# ESP32-S31 register map
Vendor: ESPRESSIF SYSTEMS (SHANGHAI) CO., LTD.; Series: ESP32 S-Series; File version: 1
CPU: RV32IMAFC r0p0, little endian, no MPU, FPU, 0 interrupt priority bits
Address unit: 32 bits
Registers are 32-bit, read-write, reset 0x0 unless marked. A register's access mark holds for its fields unless they carry their own. Offsets are from the block's base; [hi:lo] are bit positions; {n}, {i} and the like mark numbered series.

## GPIO_EXT — GPIO_EXT Peripheral
Base 0x20583E00
0x00 CLOCK_GATE — Clock Gating Configure Register
  [0] CLK_EN — Clock enable bit of configuration registers for sigma delta modulation.
0x04 SIGMADELTA_MISC — MISC Register
  [0] SIGMADELTA_CLK_EN — Configures whether or not to enable the clock for sigma delta modulation.\\ 0: Not enable\\ 1: Enable\\%\label{fielddesc:GPIOSDSPISWAP}- [GPIOSD_SPI_SWAP] Reserved.
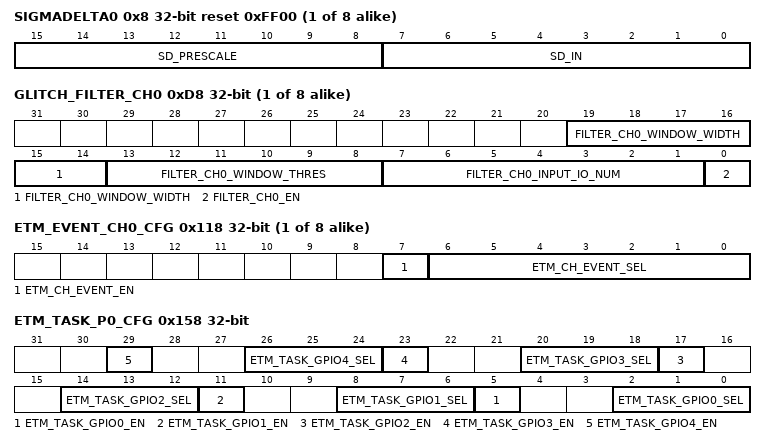
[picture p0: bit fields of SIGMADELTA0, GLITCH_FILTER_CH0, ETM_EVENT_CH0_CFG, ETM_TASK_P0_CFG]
{0x8+4i} SIGMADELTA{i} (i=0..7) reset 0xFF00 — Duty cycle configuration register for SDM channel {i}
  [15:8] SD_PRESCALE — Configures the divider value to divide IO MUX operating clock. \\
  [7:0] SD_IN — Configures the duty cycle of sigma delta modulation output. \\
{0xD8+4i} GLITCH_FILTER_CH{i} (i=0..7) — Glitch Filter Configure Register of Channel{i}
  [19:14] FILTER_CH0_WINDOW_WIDTH — Configures the window width for Glitch Filter. The effective value of window width is 0 ~ 63. \\ Measurement unit: IO MUX operating clock cycle\\
  [13:8] FILTER_CH0_WINDOW_THRES — Configures the window threshold for Glitch Filter. The window threshold should be less than or equal to GPIOSD_FILTER_CH%s_WINDOW_WIDTH.\\ %see DOC-4768\\ Measurement unit: IO MUX operating clock cycle\\
  [7:1] FILTER_CH0_INPUT_IO_NUM — Configures to select the input GPIO for Glitch Filter. \\ 0: Select GPIO0\\ 1: Select GPIO1\\ ......\\ 61: Select GPIO61\\ 62: Select GPIO62\\ 63 ~ 127: Reserved\\
  [0] FILTER_CH0_EN — Configures whether or not to enable channel %s of Glitch Filter.\\ 0: Not enable\\ 1: Enable\\
{0x118+4i} ETM_EVENT_CH{i}_CFG (i=0..7) — ETM configuration register for channel {i}
  [7] ETM_CH_EVENT_EN — Configures whether or not to enable ETM event send.\\ 0: Not enable\\ 1: Enable\\
  [6:0] ETM_CH_EVENT_SEL — Configures to select GPIO for ETM event channel.\\ 0: Select GPIO0\\ 1: Select GPIO1\\ ......\\ 61: Select GPIO61\\ 62: Select GPIO62\\ 63 ~ 127: Reserved\\
0x158 ETM_TASK_P0_CFG — GPIO selection register 0 for ETM
  [6n+5] ETM_TASK_GPIO{n}_EN (n=0..4) — Configures whether or not to enable GPIO{n} to response ETM task.\\ 0: Not enable\\ 1: Enable\\
  [6n+2:6n] ETM_TASK_GPIO{n}_SEL (n=0..4) — Configures to select an ETM task channel for GPIO{n}.\\ 0: Select channel 0\\ 1: Select channel 1\\ ......\\ 7: Select channel 7\\
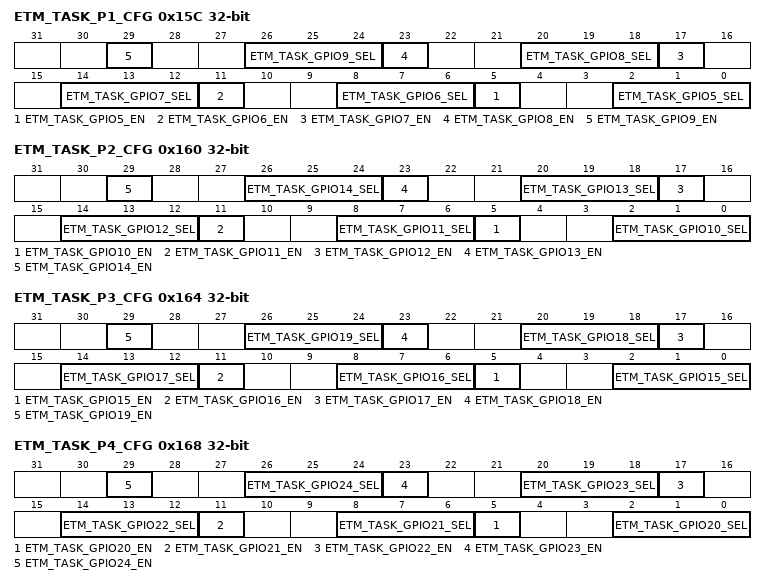
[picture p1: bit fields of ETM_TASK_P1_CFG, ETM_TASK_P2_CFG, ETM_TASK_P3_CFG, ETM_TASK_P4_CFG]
0x15C ETM_TASK_P1_CFG — GPIO selection register 1 for ETM
  [6n-25] ETM_TASK_GPIO{n}_EN (n=5..9) — Configures whether or not to enable GPIO{n} to response ETM task.\\ 0: Not enable\\ 1: Enable\\
  [6n-28:6n-30] ETM_TASK_GPIO{n}_SEL (n=5..9) — Configures to select an ETM task channel for GPIO{n}.\\ 0: Select channel 0\\ 1: Select channel 1\\ ......\\ 7: Select channel 7\\
0x160 ETM_TASK_P2_CFG — GPIO selection register 2 for ETM
  [6n-55] ETM_TASK_GPIO{n}_EN (n=10..14) — Configures whether or not to enable GPIO{n} to response ETM task.\\ 0: Not enable\\ 1: Enable\\
  [6n-58:6n-60] ETM_TASK_GPIO{n}_SEL (n=10..14) — Configures to select an ETM task channel for GPIO{n}.\\ 0: Select channel 0\\ 1: Select channel 1\\ ......\\ 7: Select channel 7\\
0x164 ETM_TASK_P3_CFG — GPIO selection register 3 for ETM
  [6n-85] ETM_TASK_GPIO{n}_EN (n=15..19) — Configures whether or not to enable GPIO{n} to response ETM task.\\ 0: Not enable\\ 1: Enable\\
  [6n-88:6n-90] ETM_TASK_GPIO{n}_SEL (n=15..19) — Configures to select an ETM task channel for GPIO{n}.\\ 0: Select channel 0\\ 1: Select channel 1\\ ......\\ 7: Select channel 7\\
0x168 ETM_TASK_P4_CFG — GPIO selection register 4 for ETM
  [6n-115] ETM_TASK_GPIO{n}_EN (n=20..24) — Configures whether or not to enable GPIO{n} to response ETM task.\\ 0: Not enable\\ 1: Enable\\
  [6n-118:6n-120] ETM_TASK_GPIO{n}_SEL (n=20..24) — Configures to select an ETM task channel for GPIO{n}.\\ 0: Select channel 0\\ 1: Select channel 1\\ ......\\ 7: Select channel 7\\
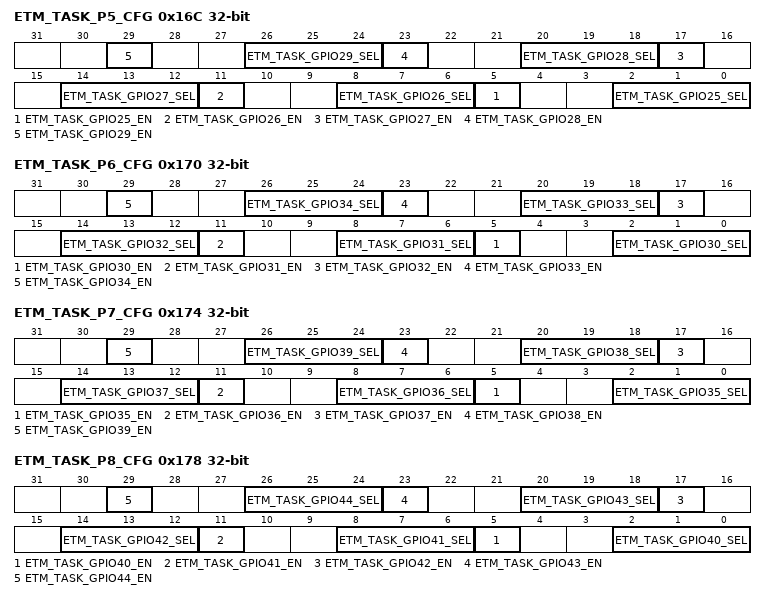
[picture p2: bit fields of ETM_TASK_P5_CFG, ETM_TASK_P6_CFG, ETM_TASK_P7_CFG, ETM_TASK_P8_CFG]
0x16C ETM_TASK_P5_CFG — GPIO selection register 5 for ETM
  [6n-145] ETM_TASK_GPIO{n}_EN (n=25..29) — Configures whether or not to enable GPIO{n} to response ETM task.\\ 0: Not enable\\ 1: Enable\\
  [6n-148:6n-150] ETM_TASK_GPIO{n}_SEL (n=25..29) — Configures to select an ETM task channel for GPIO{n}.\\ 0: Select channel 0\\ 1: Select channel 1\\ ......\\ 7: Select channel 7\\
0x170 ETM_TASK_P6_CFG — GPIO selection register 6 for ETM
  [6n-175] ETM_TASK_GPIO{n}_EN (n=30..34) — Configures whether or not to enable GPIO{n} to response ETM task.\\ 0: Not enable\\ 1: Enable\\
  [6n-178:6n-180] ETM_TASK_GPIO{n}_SEL (n=30..34) — Configures to select an ETM task channel for GPIO{n}.\\ 0: Select channel 0\\ 1: Select channel 1\\ ......\\ 7: Select channel 7\\
0x174 ETM_TASK_P7_CFG — GPIO selection register 7 for ETM
  [6n-205] ETM_TASK_GPIO{n}_EN (n=35..39) — Configures whether or not to enable GPIO{n} to response ETM task.\\ 0: Not enable\\ 1: Enable\\
  [6n-208:6n-210] ETM_TASK_GPIO{n}_SEL (n=35..39) — Configures to select an ETM task channel for GPIO{n}.\\ 0: Select channel 0\\ 1: Select channel 1\\ ......\\ 7: Select channel 7\\
0x178 ETM_TASK_P8_CFG — GPIO selection register 8 for ETM
  [6n-235] ETM_TASK_GPIO{n}_EN (n=40..44) — Configures whether or not to enable GPIO{n} to response ETM task.\\ 0: Not enable\\ 1: Enable\\
  [6n-238:6n-240] ETM_TASK_GPIO{n}_SEL (n=40..44) — Configures to select an ETM task channel for GPIO{n}.\\ 0: Select channel 0\\ 1: Select channel 1\\ ......\\ 7: Select channel 7\\
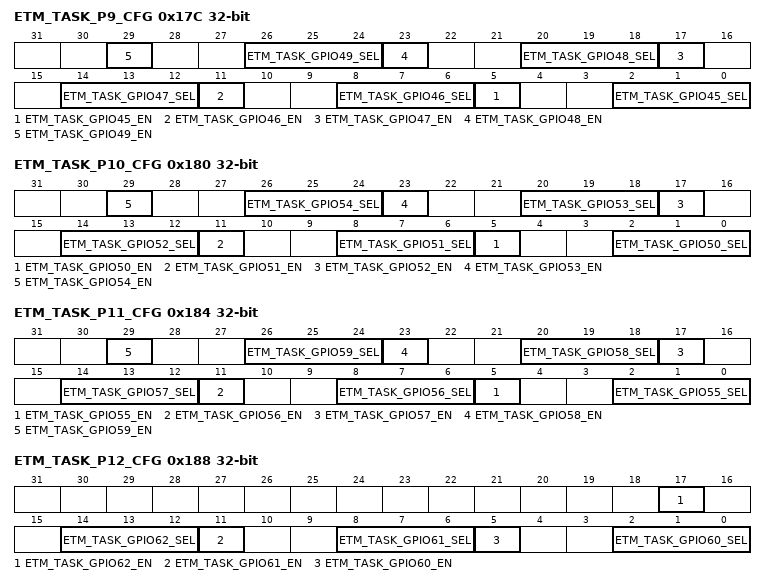
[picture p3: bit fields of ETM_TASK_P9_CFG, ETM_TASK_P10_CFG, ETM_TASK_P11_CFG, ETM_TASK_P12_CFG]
0x17C ETM_TASK_P9_CFG — GPIO selection register 9 for ETM
  [6n-265] ETM_TASK_GPIO{n}_EN (n=45..49) — Configures whether or not to enable GPIO{n} to response ETM task.\\ 0: Not enable\\ 1: Enable\\
  [6n-268:6n-270] ETM_TASK_GPIO{n}_SEL (n=45..49) — Configures to select an ETM task channel for GPIO{n}.\\ 0: Select channel 0\\ 1: Select channel 1\\ ......\\ 7: Select channel 7\\
0x180 ETM_TASK_P10_CFG — GPIO selection register 10 for ETM
  [6n-295] ETM_TASK_GPIO{n}_EN (n=50..54) — Configures whether or not to enable GPIO{n} to response ETM task.\\ 0: Not enable\\ 1: Enable\\
  [6n-298:6n-300] ETM_TASK_GPIO{n}_SEL (n=50..54) — Configures to select an ETM task channel for GPIO{n}.\\ 0: Select channel 0\\ 1: Select channel 1\\ ......\\ 7: Select channel 7\\
0x184 ETM_TASK_P11_CFG — GPIO selection register 11 for ETM
  [6n-325] ETM_TASK_GPIO{n}_EN (n=55..59) — Configures whether or not to enable GPIO{n} to response ETM task.\\ 0: Not enable\\ 1: Enable\\
  [6n-328:6n-330] ETM_TASK_GPIO{n}_SEL (n=55..59) — Configures to select an ETM task channel for GPIO{n}.\\ 0: Select channel 0\\ 1: Select channel 1\\ ......\\ 7: Select channel 7\\
0x188 ETM_TASK_P12_CFG — GPIO selection register 12 for ETM
  [17] ETM_TASK_GPIO62_EN — Configures whether or not to enable GPIO62 to response ETM task.\\ 0: Not enable\\ 1: Enable\\
  [14:12] ETM_TASK_GPIO62_SEL — Configures to select an ETM task channel for GPIO62.\\ 0: Select channel 0\\ 1: Select channel 1\\ ......\\ 7: Select channel 7\\
  [11] ETM_TASK_GPIO61_EN — Configures whether or not to enable GPIO61 to response ETM task.\\ 0: Not enable\\ 1: Enable\\
  [8:6] ETM_TASK_GPIO61_SEL — Configures to select an ETM task channel for GPIO61.\\ 0: Select channel 0\\ 1: Select channel 1\\ ......\\ 7: Select channel 7\\
  [5] ETM_TASK_GPIO60_EN — Configures whether or not to enable GPIO60 to response ETM task.\\ 0: Not enable\\ 1: Enable\\
  [2:0] ETM_TASK_GPIO60_SEL — Configures to select an ETM task channel for GPIO60.\\ 0: Select channel 0\\ 1: Select channel 1\\ ......\\ 7: Select channel 7\\
0x1FC VERSION reset 0x2508150 — Version control register
  [27:0] DATE — Version control register.
